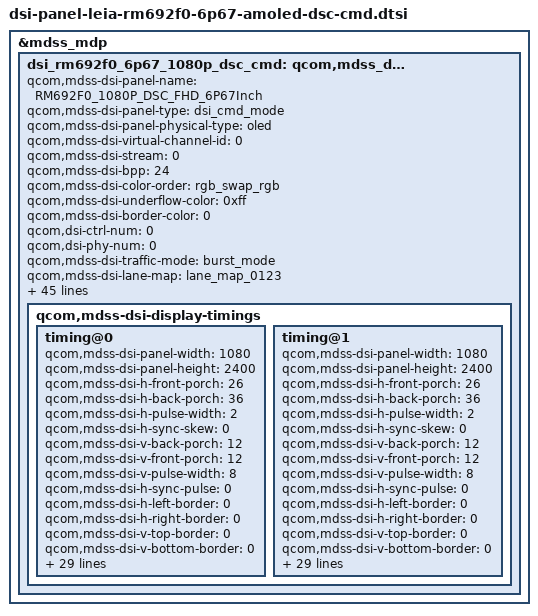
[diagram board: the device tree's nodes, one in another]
&mdss_mdp {
	dsi_rm692f0_6p67_1080p_dsc_cmd: qcom,mdss_dsi_rm692f0_6p67_1080p_dsc_cmd {
		qcom,mdss-dsi-panel-name =
				"RM692F0_1080P_DSC_FHD_6P67Inch";
		qcom,mdss-dsi-panel-type = "dsi_cmd_mode";
		qcom,mdss-dsi-panel-physical-type = "oled";
		qcom,mdss-dsi-virtual-channel-id = <0>;
		qcom,mdss-dsi-stream = <0>;
		qcom,mdss-dsi-bpp = <24>;
		qcom,mdss-dsi-color-order = "rgb_swap_rgb";
		qcom,mdss-dsi-underflow-color = <0xff>;
		qcom,mdss-dsi-border-color = <0>;
		qcom,dsi-ctrl-num = <0>;
		qcom,dsi-phy-num = <0>;
		qcom,mdss-dsi-traffic-mode = "burst_mode";
		qcom,mdss-dsi-lane-map = "lane_map_0123";
		qcom,mdss-dsi-lane-0-state;
		qcom,mdss-dsi-lane-1-state;
		qcom,mdss-dsi-lane-2-state;
		qcom,mdss-dsi-lane-3-state;
		qcom,mdss-dsi-lp11-init;
		qcom,mdss-dsi-tx-eot-append;
		qcom,mdss-dsi-bllp-eof-power-mode;
		qcom,mdss-dsi-bllp-power-mode;
		qcom,mdss-dsi-dma-trigger = "trigger_sw";
		qcom,mdss-dsi-mdp-trigger = "none";
		qcom,mdss-dsi-reset-sequence = <1 10>, <0 10>, <1 40>;
		qcom,mdss-dsi-te-pin-select = <1>;
		qcom,mdss-dsi-te-dcs-command = <1>;
		qcom,mdss-dsi-te-check-enable;
		qcom,mdss-dsi-te-using-te-pin;
		qcom,mdss-dsi-bl-min-level = <1>;
		qcom,mdss-dsi-bl-max-level = <2047>;
		qcom,mdss-dsi-bl-pmic-control-type = "bl_ctrl_dcs";
		qcom,mdss-dsi-panel-hdr-enabled;
		qcom,mdss-dsi-panel-hdr-color-primaries = <14500 15500 34015
			15980 13030 34670 6950 2565>;
		qcom,mdss-dsi-panel-peak-brightness = <6680000>;
		qcom,mdss-dsi-panel-blackness-level = <20>;
		qcom,mdss-pan-physical-width-dimension = <71>;
		qcom,mdss-pan-physical-height-dimension = <157>;
		qcom,bl-dcs-cmd-state = "dsi_lp_mode";
		qcom,mdss-dsi-display-timings {
			timing@0 {
				qcom,mdss-dsi-panel-width = <1080>;
				qcom,mdss-dsi-panel-height = <2400>;
				qcom,mdss-dsi-h-front-porch = <26>;
				qcom,mdss-dsi-h-back-porch = <36>;
				qcom,mdss-dsi-h-pulse-width = <2>;
				qcom,mdss-dsi-h-sync-skew = <0>;
				qcom,mdss-dsi-v-back-porch = <12>;
				qcom,mdss-dsi-v-front-porch = <12>;
				qcom,mdss-dsi-v-pulse-width = <8>;
				qcom,mdss-dsi-h-sync-pulse = <0>;
				qcom,mdss-dsi-h-left-border = <0>;
				qcom,mdss-dsi-h-right-border = <0>;
				qcom,mdss-dsi-v-top-border = <0>;
				qcom,mdss-dsi-v-bottom-border = <0>;
				qcom,mdss-dsi-panel-framerate = <60>;
				qcom,mdss-dsi-panel-clockrate = <885650000>;
				qcom,mdss-dsi-on-command =[
					/* AOD Power Mode */
					15 01 00 00 10 00 02 fe 40
					15 01 00 00 00 00 02 6f 00
					/* VESA ON */
					15 01 00 00 10 00 02 fe 00
					15 01 00 00 00 00 02 fa 01
					15 01 00 00 00 00 02 fe d0
					15 01 00 00 00 00 02 42 81
					/* FPS 60 */
					15 01 00 00 00 00 02 fe 84
					15 01 00 00 00 00 02 e0 90
					/* init code */
					15 01 00 00 00 00 02 fe 00
					15 01 00 00 00 00 02 5e 01
					15 01 00 00 00 00 02 c2 08
					15 01 00 00 00 00 02 35 00
					39 01 00 00 00 00 03 51 00 00
					05 01 00 00 A0 00 01 11
					05 01 00 00 14 00 01 29
				];
				qcom,mdss-dsi-off-command = [
					05 01 00 00 93 00 01 28
					05 01 00 00 05 00 01 10
				];
				qcom,mdss-dsi-on-command-state = "dsi_lp_mode";
				qcom,mdss-dsi-off-command-state = "dsi_lp_mode";
				qcom,mdss-dsi-lp1-command = [
					15 01 00 00 00 00 02 FE 84
					15 01 00 00 00 00 02 E0 90
					15 01 00 00 00 00 02 FE 00
					05 01 00 00 00 00 01 39
					15 01 00 00 00 00 02 FE A0
					15 01 00 00 00 00 02 1F 16
					15 01 00 00 00 00 02 FE 00
				];
				qcom,mdss-dsi-lp1-command-state =
					"dsi_lp_mode";
				qcom,mdss-dsi-nolp-command = [
					15 01 00 00 00 00 02 FE 00
					05 01 00 00 00 00 01 38
					15 01 00 00 00 00 02 FE 84
					15 01 00 00 00 00 02 E0 90
					05 01 00 00 14 00 01 39
					15 01 00 00 00 00 02 FE A0
					15 01 00 00 00 00 02 1F 1E
					15 01 00 00 00 00 02 FE 00
				];
				qcom,mdss-dsi-nolp-command-state =
					"dsi_lp_mode";
				qcom,mdss-dsi-timing-switch-command = [
					15 00 00 40 00 00 02 FE 84
					15 00 00 40 00 00 02 E0 90
					15 00 00 00 00 00 02 FE 00
				];
				qcom,mdss-dsi-timing-switch-command-state =
				"dsi_lp_mode";
				qcom,compression-mode = "dsc";
				qcom,mdss-dsc-slice-height = <12>;
				qcom,mdss-dsc-slice-width = <1080>;
				qcom,mdss-dsc-slice-per-pkt = <1>;
				qcom,mdss-dsc-bit-per-component = <8>;
				qcom,mdss-dsc-bit-per-pixel = <8>;
				qcom,mdss-dsc-block-prediction-enable;
			};
			timing@1 {
				qcom,mdss-dsi-panel-width = <1080>;
				qcom,mdss-dsi-panel-height = <2400>;
				qcom,mdss-dsi-h-front-porch = <26>;
				qcom,mdss-dsi-h-back-porch = <36>;
				qcom,mdss-dsi-h-pulse-width = <2>;
				qcom,mdss-dsi-h-sync-skew = <0>;
				qcom,mdss-dsi-v-back-porch = <12>;
				qcom,mdss-dsi-v-front-porch = <12>;
				qcom,mdss-dsi-v-pulse-width = <8>;
				qcom,mdss-dsi-h-sync-pulse = <0>;
				qcom,mdss-dsi-h-left-border = <0>;
				qcom,mdss-dsi-h-right-border = <0>;
				qcom,mdss-dsi-v-top-border = <0>;
				qcom,mdss-dsi-v-bottom-border = <0>;
				qcom,mdss-dsi-panel-framerate = <90>;
				qcom,mdss-dsi-panel-clockrate = <886000000>;
				qcom,mdss-dsi-on-command =[
					/* AOD Power Mode */
					15 01 00 00 10 00 02 fe 40
					15 01 00 00 00 00 02 6f 00
					/* VESA ON */
					15 01 00 00 10 00 02 fe 00
					15 01 00 00 00 00 02 fa 01
					15 01 00 00 00 00 02 fe d0
					15 01 00 00 00 00 02 42 81
					/* FPS 90 */
					15 01 00 00 00 00 02 fe 84
					15 01 00 00 00 00 02 e0 80
					/* init code */
					15 01 00 00 00 00 02 fe 00
					15 01 00 00 00 00 02 5e 01
					15 01 00 00 00 00 02 c2 08
					15 01 00 00 00 00 02 35 00
					39 01 00 00 00 00 03 51 00 00
					05 01 00 00 A0 00 01 11
					05 01 00 00 14 00 01 29
				];
				qcom,mdss-dsi-off-command = [
					05 01 00 00 93 00 01 28
					05 01 00 00 05 00 01 10
				];
				qcom,mdss-dsi-on-command-state = "dsi_lp_mode";
				qcom,mdss-dsi-off-command-state = "dsi_lp_mode";
				qcom,mdss-dsi-lp1-command = [
					15 01 00 00 00 00 02 FE 84
					15 01 00 00 00 00 02 E0 90
					15 01 00 00 00 00 02 FE 00
					05 01 00 00 00 00 01 39
					15 01 00 00 00 00 02 FE A0
					15 01 00 00 00 00 02 1F 16
					15 01 00 00 00 00 02 FE 00
				];
				qcom,mdss-dsi-lp1-command-state =
					"dsi_lp_mode";
				qcom,mdss-dsi-nolp-command = [
					15 01 00 00 00 00 02 FE 00
					05 01 00 00 00 00 01 38
					15 01 00 00 00 00 02 FE 84
					15 01 00 00 00 00 02 E0 90
					05 01 00 00 14 00 01 39
					15 01 00 00 00 00 02 FE A0
					15 01 00 00 00 00 02 1F 1E
					15 01 00 00 00 00 02 FE 00
				];
				qcom,mdss-dsi-nolp-command-state =
					"dsi_lp_mode";
				qcom,mdss-dsi-timing-switch-command = [
					15 00 00 40 00 00 02 FE 84
					15 00 00 40 00 00 02 E0 80
					15 00 00 00 00 00 02 FE 00
				];
				qcom,mdss-dsi-timing-switch-command-state =
				"dsi_lp_mode";
				qcom,compression-mode = "dsc";
				qcom,mdss-dsc-slice-height = <12>;
				qcom,mdss-dsc-slice-width = <1080>;
				qcom,mdss-dsc-slice-per-pkt = <1>;
				qcom,mdss-dsc-bit-per-component = <8>;
				qcom,mdss-dsc-bit-per-pixel = <8>;
				qcom,mdss-dsc-block-prediction-enable;
			};
		};
	};
};

/* panel feature */
&dsi_rm692f0_6p67_1080p_dsc_cmd {
    /* zte disp feature */
	zte,hbm_enabled;
	zte,hdr_enabled;
	zte,fps_enabled;
	zte,aod_enabled;
	zte,color_space_enabled;
	zte,bl_limit_enabled;
	zte,spr_enabled;
	zte,hdr_brightness = <0xFFF>;
	zte,aod-exit-delay-time = <150>;
	zte,hdr_threshold = <0xFFF>;
	qcom,mdss-dsi-display-timings {
		timing@0 {
		   #include "dsi-panel-leia-rm692f0-common.dtsi"
		};
		timing@1 {
		   #include "dsi-panel-leia-rm692f0-common.dtsi"
		};
	};
};

/* panel supply */
&dsi_rm692f0_6p67_1080p_dsc_cmd {
	qcom,panel-supply-entries = <&dsi_panel_pwr_supply_z50u>;
	qcom,mdss-dsi-bl-pmic-control-type = "bl_ctrl_dcs";
	qcom,mdss-brightness-max-level = <2047>;
	qcom,mdss-dsi-bl-inverted-dbv;
	qcom,platform-reset-gpio = <&tlmm 133 0>;
	qcom,ulps-enabled;
	qcom,dsi-select-clocks = "pll_byte_clk0", "pll_dsi_clk0";
	qcom,mdss-dsi-display-timings {
		timing@0 {
			/* DPHY regular margins */
			qcom,mdss-dsi-panel-phy-timings = [00 1E 08 07 18 22 08
				08 08 02 04 00 1A 0C];
			qcom,display-topology = <1 1 1>;
			qcom,default-topology-index = <0>;
		};
		timing@1 {
			/* DPHY regular margins */
			qcom,mdss-dsi-panel-phy-timings = [00 1E 08 07 18 22 08
				08 08 02 04 00 1A 0C];
			qcom,display-topology = <1 1 1>;
			qcom,default-topology-index = <0>;
		};
	};
};
